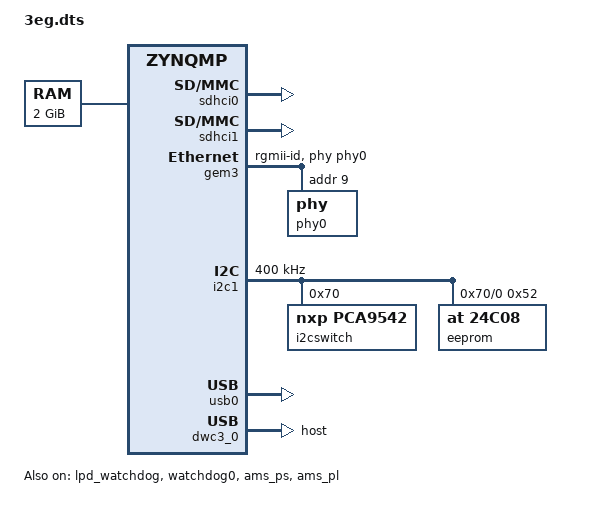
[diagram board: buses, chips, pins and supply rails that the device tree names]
/*
 * CAUTION: This file is automatically generated by Xilinx.
 * Version: XSCT 2018.3
 * Today is: Fri May 10 09:09:40 2019
 */


/dts-v1/;
#include "zynqmp.dtsi"
#include "zynqmp-clk-ccf.dtsi"
#include "pl.dtsi"
#include "pcw.dtsi"
/ {
	chosen {
		bootargs = "console=/dev/ttyPS0,115200 root=/dev/mmcblk1p2 rw earlyprintk earlycon clk_ignore_unused";
		stdout-path = "serial0:115200n8";
	};
	aliases {
		ethernet0 = &gem3;
		i2c0 = &i2c1;
		serial0 = &uart0;
		serial1 = &uart1;
		spi0 = &qspi;
		usb0 = &usb0;
	};
	memory {
		device_type = "memory";
		reg = <0x0 0x0 0x0 0x7ff00000>;
	};
};
&sdhci0 {
	clock-frequency = <199998001>;
	status = "okay";
	xlnx,mio_bank = <0x0>;
	nvmem-cells = <&soc_revision>;
	nvmem-cell-names = "soc_revision";
	#clock-cells = <1>;
	clock-output-names = "clk_out_sd0", "clk_in_sd0";
};
&sdhci1 {
	clock-frequency = <199998001>;
	status = "okay";
	disable-wp;
	no-1-8-v;
	xlnx,mio_bank = <0x1>;
	nvmem-cells = <&soc_revision>;
	nvmem-cell-names = "soc_revision";
	#clock-cells = <1>;
	clock-output-names = "clk_out_sd1", "clk_in_sd1";
};

&gem3 {
	status = "okay";
	local-mac-address = [00 0a 35 00 02 90];
	phy-mode = "rgmii-id";
	phy-handle = <&phy0>;
	phy0: phy@9 {
		reg = <0x9>;
		ti,rx-internal-delay = <0x5>;
		ti,tx-internal-delay = <0x5>;
		ti,fifo-depth = <0x1>;
	};
};

&i2c1 {
	status = "okay";
	clock-frequency = <400000>;

	i2cswitch@70 { /* U7 on UZ3EG SOM */
		compatible = "nxp,pca9542";
		#address-cells = <1>;
		#size-cells = <0>;
		reg = <0x70>;
		i2c@0 { /* i2c mw 70 0 1 */
			#address-cells = <1>;
			#size-cells = <0>;
			reg = <0>;
			/* IIC_EEPROM */
			eeprom@52 { /* U5 on UZ3EG IO Carrier*/
				compatible = "at,24c08";
				reg = <0x52>;
			};
		};
	};
};

&amba_pl {
	bssif_0: bssif@80000000 {
	   compatible = "bssif-1.0";
	   reg = <0x0 0x80000000 0x0 0x10000>;
    };
	misc_clk_0: misc_clk_0 {
		#clock-cells = <0>;
		clock-frequency = <299997000>;
		compatible = "fixed-clock";
	};
};

/* ULPI SMSC USB3320 */
&usb0 {
	status = "okay";
};

&dwc3_0 {
	status = "okay";
	dr_mode = "host";
	phy-names = "usb3-phy";
};
&lpd_watchdog {
	status = "okay";
};
&watchdog0 {
	status = "okay";
};
&ams_ps {
	status = "okay";
};
&ams_pl {
	status = "okay";
};
